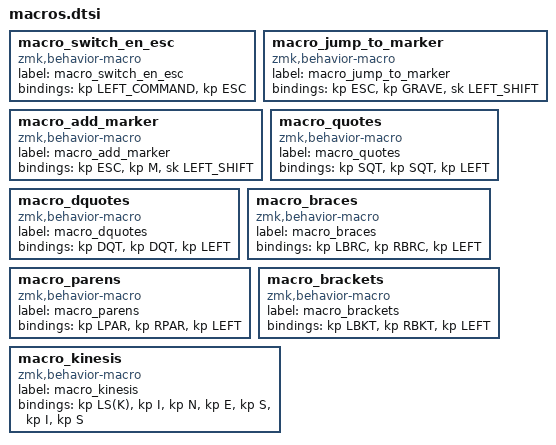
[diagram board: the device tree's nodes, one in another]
macro_switch_en_esc: macro_switch_en_esc{
compatible = "zmk,behavior-macro";
label = "macro_switch_en_esc";
#binding-cells = <0>;
bindings = <&kp LEFT_COMMAND>, <&kp ESC>;
};
macro_jump_to_marker: macro_jump_to_marker{
compatible = "zmk,behavior-macro";
label = "macro_jump_to_marker";
#binding-cells = <0>;
bindings = <&kp ESC>, <&kp GRAVE>, <&sk LEFT_SHIFT>;
};
macro_add_marker: macro_add_marker{
compatible = "zmk,behavior-macro";
label = "macro_add_marker";
#binding-cells = <0>;
bindings = <&kp ESC>, <&kp M>, <&sk LEFT_SHIFT>;
};
macro_quotes: macro_quotes{
compatible = "zmk,behavior-macro";
label = "macro_quotes";
#binding-cells = <0>;
bindings = <&kp SQT>, <&kp SQT>, <&kp LEFT>;
};
macro_dquotes: macro_dquotes{
compatible = "zmk,behavior-macro";
label = "macro_dquotes";
#binding-cells = <0>;
bindings = <&kp DQT>, <&kp DQT>, <&kp LEFT>;
};
macro_braces: macro_braces{
compatible = "zmk,behavior-macro";
label = "macro_braces";
#binding-cells = <0>;
bindings = <&kp LBRC>, <&kp RBRC>, <&kp LEFT>;
};
macro_parens: macro_parens{
compatible = "zmk,behavior-macro";
label = "macro_parens";
#binding-cells = <0>;
bindings = <&kp LPAR>, <&kp RPAR>, <&kp LEFT>;
};
macro_brackets: macro_brackets{
compatible = "zmk,behavior-macro";
label = "macro_brackets";
#binding-cells = <0>;
bindings = <&kp LBKT>, <&kp RBKT>, <&kp LEFT>;
};
macro_kinesis: macro_kinesis{
compatible = "zmk,behavior-macro";
label = "macro_kinesis";
#binding-cells = <0>;
bindings = <&kp LS(K)>, <&kp I>, <&kp N>, <&kp E>, <&kp S>, <&kp I>, <&kp S>;
};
